# AT90PWM1 register map
Vendor: Atmel; File version: 1.0
CPU: other r0p0, little endian, no MPU, no FPU, 4 interrupt priority bits
Registers are 8-bit, read-write, reset 0x0 unless marked. A register's access mark holds for its fields unless they carry their own. Offsets are from the block's base; [hi:lo] are bit positions; {n}, {i} and the like mark numbered series; 'fields as' and 'values as' point back to an identical list.

## PORTD — I/O Port
Base 0x00000029
0x00 PIND — Port D Input Pins
0x01 DDRD — Port D Data Direction Register
0x02 PORTD — Port D Data Register

## PORTE — I/O Port
Base 0x0000002C
0x00 PINE — Port E Input Pins
0x01 DDRE — Port E Data Direction Register
0x02 PORTE — Port E Data Register

## PSC0 — Power Stage Controller
Base 0x000000A0
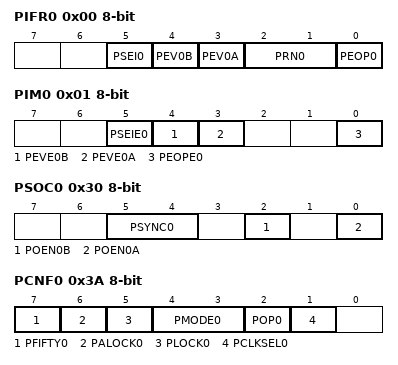
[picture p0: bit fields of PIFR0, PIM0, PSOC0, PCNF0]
0x00 PIFR0 — PSC0 Interrupt Flag Register
  [5] PSEI0 — PSC 0 Synchro Error Interrupt
  [4] PEV0B — External Event B Interrupt
  [3] PEV0A — External Event A Interrupt
  [2:1] PRN0 — Ramp Number
    {v}={v+1} (v=0..3)
  [0] PEOP0 — End of PSC0 Interrupt
0x01 PIM0 — PSC0 Interrupt Mask Register
  [5] PSEIE0 — PSC 0 Synchro Error Interrupt Enable
  [4] PEVE0B — External Event B Interrupt Enable
  [3] PEVE0A — External Event A Interrupt Enable
  [0] PEOPE0 — End of Cycle Interrupt Enable
0x30 PSOC0 — PSC0 Synchro and Output Configuration
  [5:4] PSYNC0 — Synchronization Out for ADC Selection
    0=Send signal on leading edge of PSCOUTn0; 1=Send signal on trailing edge of PSCOUTn0; 2=Send signal on leading edge of PSCOUTn1; 3=Send signal on trailing edge of PSCOUTn1
  [2] POEN0B — PSCOUT01 Output Enable
  [0] POEN0A — PSCOUT00 Output Enable
0x32 OCR0SA 16-bit (reset mask 0xFF) — Output Compare SA Register
0x34 OCR0RA 16-bit (reset mask 0xFF) — Output Compare RA Register
0x36 OCR0SB 16-bit (reset mask 0xFF) — Output Compare SB Register
0x38 OCR0RB 16-bit (reset mask 0xFF) — Output Compare RB Register
0x3A PCNF0 — PSC 0 Configuration Register
  [7] PFIFTY0 — PSC 0 Fifty
  [6] PALOCK0 — PSC 0 Autolock
  [5] PLOCK0 — PSC 0 Lock
  [4:3] PMODE0 — PSC 0 Mode
    0=One Ramp Mode; 1=Two Ramp Mode; 2=Four Ramp Mode; 3=Center Aligned Mode
  [2] POP0 — PSC 0 Output Polarity
  [1] PCLKSEL0 — PSC 0 Input Clock Select
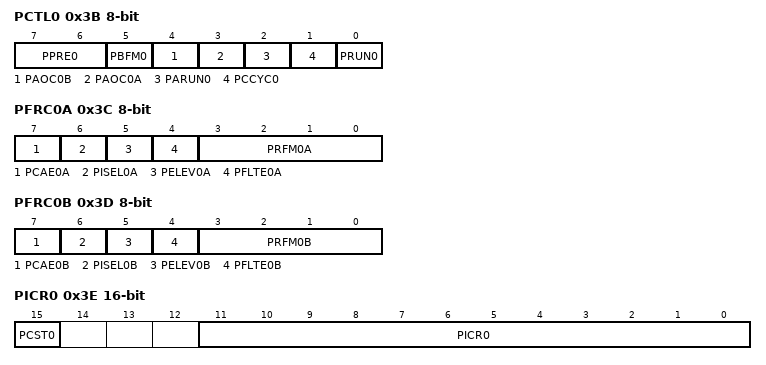
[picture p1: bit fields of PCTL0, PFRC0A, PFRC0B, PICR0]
0x3B PCTL0 — PSC 0 Control Register
  [7:6] PPRE0 — PSC 0 Prescaler Selects
    0=No divider on PSC input clock; 1=Divide the PSC input clock by 4; 2=Divide the PSC input clock by 16; 3=Divide the PSC input clock by 64
  [5] PBFM0 — PSC 0 Balance Flank Width Modulation
  [4] PAOC0B — PSC 0 Asynchronous Output Control B
  [3] PAOC0A — PSC 0 Asynchronous Output Control A
  [2] PARUN0 — PSC0 Auto Run
  [1] PCCYC0 — PSC0 Complete Cycle
  [0] PRUN0 — PSC 0 Run
0x3C PFRC0A — PSC 0 Input A Control
  [7] PCAE0A — PSC 0 Capture Enable Input Part A
  [6] PISEL0A — PSC 0 Input Select for Part A
  [5] PELEV0A — PSC 0 Edge Level Selector on Input Part A
  [4] PFLTE0A — PSC 0 Filter Enable on Input Part A
  [3:0] PRFM0A — PSC 0 Retrigger and Fault Mode for Part A
    0=No action, PSC Input is ignored; 1=Stop signal, Jump to Opposite Dead-Time and Wait; 2=Stop signal, Execute Opposite Dead-Time and Wait; 3=Stop signal, Execute Opposite while Fault active; 4=Deactivate outputs without changing timing; 5=Stop signal and Insert Dead-Time; 6=Stop signal, Jump to Opposite Dead-Time and Wait; 7=Halt PSC and Wait for Software Action; 8=Edge Retrigger PSC; 9=Fixed Frequency Edge Retrigger PSC; 14=Fixed Frequency Edge Retrigger PSC and Disactivate Output
0x3D PFRC0B — PSC 0 Input B Control
  [7] PCAE0B — PSC 0 Capture Enable Input Part B
  [6] PISEL0B — PSC 0 Input Select for Part B
  [5] PELEV0B — PSC 0 Edge Level Selector on Input Part B
  [4] PFLTE0B — PSC 0 Filter Enable on Input Part B
  [3:0] PRFM0B — PSC 0 Retrigger and Fault Mode for Part B
    values as PFRC0A.PRFM0A
0x3E PICR0 16-bit (reset mask 0xFF) — PSC 0 Input Capture Register
  [15] PCST0 — PSC 0 Capture Software Trig bit
  [11:0] PICR0 — PSC 0 Capture Register

## PSC1 — Power Stage Controller
Base 0x000000E0
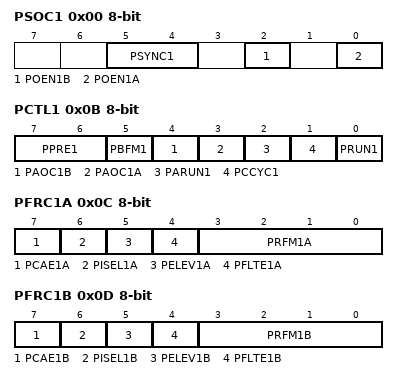
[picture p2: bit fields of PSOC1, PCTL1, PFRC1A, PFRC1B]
0x00 PSOC1 — PSC1 Synchro and Output Configuration
  [5:4] PSYNC1 — Synchronization Out for ADC Selection
    0=Send signal on leading edge of PSCOUTn0; 1=Send signal on trailing edge of PSCOUTn0; 2=Send signal on leading edge of PSCOUTn1; 3=Send signal on trailing edge of PSCOUTn1
  [2] POEN1B — PSCOUT11 Output Enable
  [0] POEN1A — PSCOUT10 Output Enable
0x0B PCTL1 — PSC 1 Control Register
  [7:6] PPRE1 — PSC 1 Prescaler Selects
    0=No divider on PSC input clock; 1=Divide the PSC input clock by 4; 2=Divide the PSC input clock by 16; 3=Divide the PSC input clock by 64
  [5] PBFM1 — Balance Flank Width Modulation
  [4] PAOC1B — PSC 1 Asynchronous Output Control B
  [3] PAOC1A — PSC 1 Asynchronous Output Control A
  [2] PARUN1 — PSC1 Auto Run
  [1] PCCYC1 — PSC1 Complete Cycle
  [0] PRUN1 — PSC 1 Run
0x0C PFRC1A — PSC 1 Input B Control
  [7] PCAE1A — PSC 1 Capture Enable Input Part A
  [6] PISEL1A — PSC 1 Input Select for Part A
  [5] PELEV1A — PSC 1 Edge Level Selector on Input Part A
  [4] PFLTE1A — PSC 1 Filter Enable on Input Part A
  [3:0] PRFM1A — PSC 1 Retrigger and Fault Mode for Part A
    0=No action, PSC Input is ignored; 1=Stop signal, Jump to Opposite Dead-Time and Wait; 2=Stop signal, Execute Opposite Dead-Time and Wait; 3=Stop signal, Execute Opposite while Fault active; 4=Deactivate outputs without changing timing; 5=Stop signal and Insert Dead-Time; 6=Stop signal, Jump to Opposite Dead-Time and Wait; 7=Halt PSC and Wait for Software Action; 8=Edge Retrigger PSC; 9=Fixed Frequency Edge Retrigger PSC; 14=Fixed Frequency Edge Retrigger PSC and Disactivate Output
0x0D PFRC1B — PSC 1 Input B Control
  [7] PCAE1B — PSC 1 Capture Enable Input Part B
  [6] PISEL1B — PSC 1 Input Select for Part B
  [5] PELEV1B — PSC 1 Edge Level Selector on Input Part B
  [4] PFLTE1B — PSC 1 Filter Enable on Input Part B
  [3:0] PRFM1B — PSC 1 Retrigger and Fault Mode for Part B
    values as PFRC1A.PRFM1A
0x0E PICR1 16-bit (reset mask 0xFF) — PSC 1 Input Capture Register
